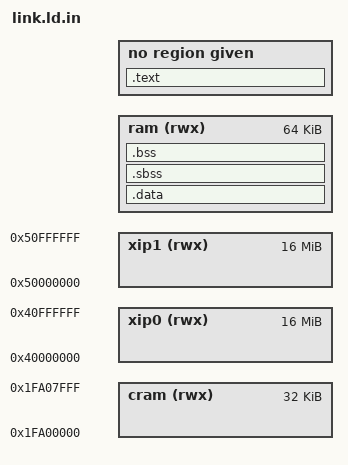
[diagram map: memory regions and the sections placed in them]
OUTPUT_ARCH(CONFIG_ARCH)

ENTRY(_start)

GROUP(-lc -lgcc)

MEMORY
{
    xip0 (rwx) : ORIGIN = 0x40000000, LENGTH = 0x1000000
    xip1 (rwx) : ORIGIN = 0x50000000, LENGTH = 0x1000000
    ram (rwx)  : ORIGIN = CONFIG_RAM_ADDR, LENGTH = 0x10000
    cram (rwx) : ORIGIN = 0x1fa00000, LENGTH = 0x8000
}

SECTIONS
{
  .text ORIGIN(CONFIG_REGION) : {
    *(.text.boot)
    *(.text)
    *(.text.*)
    *(.rodata)
    *(.rodata.*)
    *(.got)
    *(.got.*)
    . = ALIGN(4);
  } > CONFIG_REGION

  __text_end = ABSOLUTE(.);

  .data : AT (__text_end) {
    __data_start = ABSOLUTE(.);
    *(.data)
    *(.data.*)
    *(.gnu.*)
    . = ALIGN(4);
    _gp = ABSOLUTE(.);  /* Base of small data (for MIPS) */
    *(.sdata)
    *(.sdata.*)
    . = ALIGN(4);
    __data_end = ABSOLUTE(.);
  } > ram

  .sbss (NOLOAD) : {
    __bss_start = ABSOLUTE(.);
    *(.sbss)
    *(.sbss.*)
    *(.scommon)
  } > ram

  .bss (NOLOAD) : {
    *(.bss)
    *(.bss.*)
    *(COMMON)
    . = ALIGN(4);
    __bss_end = ABSOLUTE(.);
    __bss_length = ABSOLUTE(.) - __bss_start;
  } > ram

  _stack = ORIGIN(ram) + LENGTH(ram) - 0x20;

  /DISCARD/ : {
    *(.reginfo)
    *(.MIPS.abiflags)
    *(.dynamic)
    *(.interp)
    *(.rela.*)
    *(.eh_frame_hdr)
    *(.dynstr)
    *(.hash)
    *(.dynsym)
    *(.gnu.hash)
    *(.comment)
  }
}
